VERSION "DeviceStatus v1"

NS_ :

BS_:

BU_: TEENSY HOST

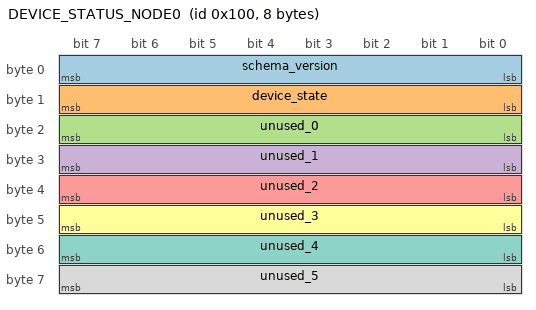
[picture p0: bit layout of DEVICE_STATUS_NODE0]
BO_ 256 DEVICE_STATUS_NODE0: 8 TEENSY
 SG_ schema_version : 0|8@1+  (1,0) [0|255] "" HOST
 SG_ device_state   : 8|8@1+  (1,0) [0|2]   "" HOST
 SG_ unused_0       : 16|8@1+ (1,0) [0|255] "" HOST
 SG_ unused_1       : 24|8@1+ (1,0) [0|255] "" HOST
 SG_ unused_2       : 32|8@1+ (1,0) [0|255] "" HOST
 SG_ unused_3       : 40|8@1+ (1,0) [0|255] "" HOST
 SG_ unused_4       : 48|8@1+ (1,0) [0|255] "" HOST
 SG_ unused_5       : 56|8@1+ (1,0) [0|255] "" HOST

VAL_ 256 device_state 0 "NODE_INIT" 1 "NODE_ACTIVE" 2 "NODE_FAULT";

CM_ BO_ 256 "Device status message. Actual firmware sends this at CAN ID 0x100 + nodeData.id.";
CM_ SG_ 256 schema_version "Schema version byte from nodeData.schema_version.";
CM_ SG_ 256 device_state "Raw node state enum from nodeData.state.";
CM_ SG_ 256 status_flags "Currently always 0 in firmware.";
CM_ SG_ 256 uptime_s "Currently always 0 in firmware.";
CM_ SG_ 256 heartbeat_counter "Currently always 0 in firmware.";
CM_ SG_ 256 reserved "Currently always 0 in firmware.";

BA_DEF_ BO_ "GenMsgCycleTime" INT 0 65535;
BA_ "GenMsgCycleTime" BO_ 256 1000;
